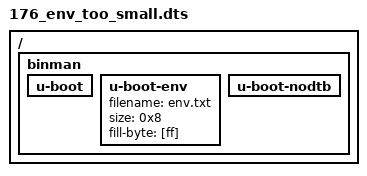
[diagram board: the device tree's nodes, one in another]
// SPDX-License-Identifier: GPL-2.0+

/dts-v1/;

/ {
	#address-cells = <1>;
	#size-cells = <1>;

	binman {
		u-boot {
		};
		u-boot-env {
			filename = "env.txt";
			size = <0x8>;
			fill-byte = [ff];
		};
		u-boot-nodtb {
		};
	};
};
